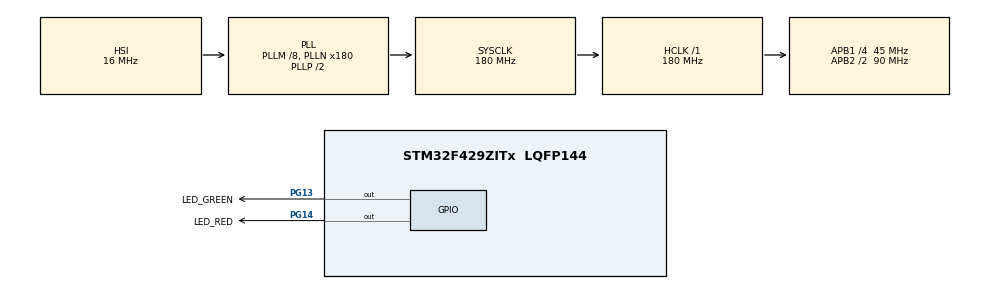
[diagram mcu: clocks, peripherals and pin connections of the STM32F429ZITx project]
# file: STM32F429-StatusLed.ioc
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Mcu.Family=STM32F4
Mcu.Name=STM32F429ZITx
Mcu.Package=LQFP144
NVIC.PriorityGroup=NVIC_PRIORITYGROUP_4
PG13.GPIO_Label=LED_GREEN
PG13.Signal=GPIO_Output
PG14.GPIO_Label=LED_RED
PG14.Signal=GPIO_Output
ProjectManager.HeapSize=0x200
ProjectManager.StackSize=0x400
ProjectManager.TargetToolchain=MDK-ARM V5.27
RCC.48MHZClocksFreq_Value=120000000
RCC.AHBFreq_Value=180000000
RCC.APB1CLKDivider=RCC_HCLK_DIV4
RCC.APB1Freq_Value=45000000
RCC.APB1TimFreq_Value=90000000
RCC.APB2CLKDivider=RCC_HCLK_DIV2
RCC.APB2Freq_Value=90000000
RCC.APB2TimFreq_Value=180000000
RCC.CortexFreq_Value=180000000
RCC.HCLKFreq_Value=180000000
RCC.HSE_VALUE=8000000
RCC.HSI_VALUE=16000000
RCC.LSE_VALUE=32768
RCC.PLLM=8
RCC.PLLN=180
RCC.PLLQ=3
RCC.PLLSAIN=50
RCC.SYSCLKFreq_VALUE=180000000
RCC.SYSCLKSource=RCC_SYSCLKSOURCE_PLLCLK
RCC.VCOOutputFreq_Value=360000000
board=STM32F429I-DISC1

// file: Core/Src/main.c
/* USER CODE BEGIN Header */
/**
  ******************************************************************************
  * @file           : main.c
  * @brief          : Main program body
  ******************************************************************************
  * @attention
  *
  * <h2><center>&copy; Copyright (c) 2022 STMicroelectronics.
  * All rights reserved.</center></h2>
  *
  * This software component is licensed by ST under BSD 3-Clause license,
  * the "License"; You may not use this file except in compliance with the
  * License. You may obtain a copy of the License at:
  *                        opensource.org/licenses/BSD-3-Clause
  *
  ******************************************************************************
  */
/* USER CODE END Header */
#include "main.h"

/* USER CODE BEGIN Includes */
#include "StatusLed.h"
/* USER CODE END Includes */

/* USER CODE BEGIN PV */
// On-Off 500 ms
static const StatusLed_Cycle PATTERN_0_CYCLES[] = {
  {500, 500}
};
static const StatusLed_Pattern PATTERN_0 = STATUS_LED_PATTERN(PATTERN_0_CYCLES);

static const StatusLed_Cycle PATTERN_1_CYCLES[] = {
  {100, 3000}
};
static const StatusLed_Pattern PATTERN_1 = STATUS_LED_PATTERN(PATTERN_1_CYCLES);

static const StatusLed_Cycle PATTERN_2_CYCLES[] = {
  {100, 200},
  {100, 200},
  {100, 3000},
};
static const StatusLed_Pattern PATTERN_2 = STATUS_LED_PATTERN(PATTERN_2_CYCLES);

static const StatusLed_PinConfig LED_RED = {
  LED_RED_GPIO_Port, LED_RED_Pin,
};
static const StatusLed_PinConfig LED_GREEN = {
  LED_GREEN_GPIO_Port, LED_GREEN_Pin,
};

#if STATUS_LED_MAX_NUM == -1
  static StatusLed ledRed;
  static StatusLed ledGreen;
#else
  static StatusLed* ledRed;
  static StatusLed* ledGreen;
#endif

/* USER CODE END PV */

void SystemClock_Config(void);
static void MX_GPIO_Init(void);
/* USER CODE BEGIN PFP */
void StatusLed_initPin(const StatusLed_PinConfig* config);
void StatusLed_deInitPin(const StatusLed_PinConfig* config);
void StatusLed_writePin(const StatusLed_PinConfig* config, StatusLed_PinState state);
StatusLed_Timestamp StatusLed_getTimestamp(void);

void StatusLed_onPatternFinish(StatusLed* led);

/* USER CODE END PFP */

/* USER CODE BEGIN 0 */
static const StatusLed_Driver STATUS_LED_DRIVER = {
  StatusLed_getTimestamp,
  StatusLed_initPin,
  StatusLed_writePin,
#if STATUS_LED_DEINIT
  StatusLed_deInitPin,
#endif
};
/* USER CODE END 0 */

int main(void)
{

  /* MCU Configuration--------------------------------------------------------*/

  /* Reset of all peripherals, Initializes the Flash interface and the Systick. */
  HAL_Init();

  /* Configure the system clock */
  SystemClock_Config();

  /* Initialize all configured peripherals */
  MX_GPIO_Init();
  /* USER CODE BEGIN 2 */
  StatusLed_init(&STATUS_LED_DRIVER);
 #if STATUS_LED_MAX_NUM == -1
  StatusLed_add(&ledRed, &LED_RED);
  StatusLed_add(&ledGreen, &LED_GREEN);

  StatusLed_setPattern(&ledRed, &PATTERN_0);
  StatusLed_setPattern(&ledGreen, &PATTERN_2);
 #else
  ledRed = StatusLed_new();
  StatusLed_add(ledRed, &LED_RED);
  ledGreen = StatusLed_new();
  StatusLed_add(ledGreen, &LED_GREEN);

  StatusLed_setPattern(ledRed, &PATTERN_0);
  StatusLed_setPattern(ledGreen, &PATTERN_1);
 #endif
  /* USER CODE END 2 */

  /* Infinite loop */
  /* USER CODE BEGIN WHILE */
  while (1)
  {
    HAL_Delay(StatusLed_handle());
    /* USER CODE END WHILE */

  }
}

void SystemClock_Config(void)
{
  RCC_OscInitTypeDef RCC_OscInitStruct = {0};
  RCC_ClkInitTypeDef RCC_ClkInitStruct = {0};

  /** Configure the main internal regulator output voltage
  */
  __HAL_RCC_PWR_CLK_ENABLE();
  __HAL_PWR_VOLTAGESCALING_CONFIG(PWR_REGULATOR_VOLTAGE_SCALE1);
  /** Initializes the RCC Oscillators according to the specified parameters
  * in the RCC_OscInitTypeDef structure.
  */
  RCC_OscInitStruct.OscillatorType = RCC_OSCILLATORTYPE_HSI;
  RCC_OscInitStruct.HSIState = RCC_HSI_ON;
  RCC_OscInitStruct.HSICalibrationValue = RCC_HSICALIBRATION_DEFAULT;
  RCC_OscInitStruct.PLL.PLLState = RCC_PLL_ON;
  RCC_OscInitStruct.PLL.PLLSource = RCC_PLLSOURCE_HSI;
  RCC_OscInitStruct.PLL.PLLM = 8;
  RCC_OscInitStruct.PLL.PLLN = 180;
  RCC_OscInitStruct.PLL.PLLP = RCC_PLLP_DIV2;
  RCC_OscInitStruct.PLL.PLLQ = 3;
  if (HAL_RCC_OscConfig(&RCC_OscInitStruct) != HAL_OK)
  {
    Error_Handler();
  }
  /** Activate the Over-Drive mode
  */
  if (HAL_PWREx_EnableOverDrive() != HAL_OK)
  {
    Error_Handler();
  }
  /** Initializes the CPU, AHB and APB buses clocks
  */
  RCC_ClkInitStruct.ClockType = RCC_CLOCKTYPE_HCLK|RCC_CLOCKTYPE_SYSCLK
                              |RCC_CLOCKTYPE_PCLK1|RCC_CLOCKTYPE_PCLK2;
  RCC_ClkInitStruct.SYSCLKSource = RCC_SYSCLKSOURCE_PLLCLK;
  RCC_ClkInitStruct.AHBCLKDivider = RCC_SYSCLK_DIV1;
  RCC_ClkInitStruct.APB1CLKDivider = RCC_HCLK_DIV4;
  RCC_ClkInitStruct.APB2CLKDivider = RCC_HCLK_DIV2;

  if (HAL_RCC_ClockConfig(&RCC_ClkInitStruct, FLASH_LATENCY_5) != HAL_OK)
  {
    Error_Handler();
  }
}

static void MX_GPIO_Init(void)
{
  GPIO_InitTypeDef GPIO_InitStruct = {0};

  /* GPIO Ports Clock Enable */
  __HAL_RCC_GPIOG_CLK_ENABLE();

  /*Configure GPIO pin Output Level */
  HAL_GPIO_WritePin(GPIOG, LED_GREEN_Pin|LED_RED_Pin, GPIO_PIN_RESET);

  /*Configure GPIO pins : LED_GREEN_Pin LED_RED_Pin */
  GPIO_InitStruct.Pin = LED_GREEN_Pin|LED_RED_Pin;
  GPIO_InitStruct.Mode = GPIO_MODE_OUTPUT_PP;
  GPIO_InitStruct.Pull = GPIO_NOPULL;
  GPIO_InitStruct.Speed = GPIO_SPEED_FREQ_LOW;
  HAL_GPIO_Init(GPIOG, &GPIO_InitStruct);

}

/* USER CODE BEGIN 4 */
void StatusLed_initPin(const StatusLed_PinConfig* config) {
  GPIO_InitTypeDef GPIO_InitStruct = {0};

  GPIO_InitStruct.Pin = config->Pin;
  GPIO_InitStruct.Mode = GPIO_MODE_OUTPUT_PP;
  GPIO_InitStruct.Pull = GPIO_NOPULL;
  GPIO_InitStruct.Speed = GPIO_SPEED_FREQ_LOW;
  HAL_GPIO_Init((GPIO_TypeDef*) config->IO, &GPIO_InitStruct);
}
void StatusLed_deInitPin(const StatusLed_PinConfig* config) {
  HAL_GPIO_DeInit((GPIO_TypeDef*) config->IO, config->Pin);
}
void StatusLed_writePin(const StatusLed_PinConfig* config, StatusLed_PinState state) {
  HAL_GPIO_WritePin((GPIO_TypeDef*) config->IO, config->Pin, (GPIO_PinState) state);
}
StatusLed_Timestamp StatusLed_getTimestamp(void) {
  return (StatusLed_Timestamp) HAL_GetTick();
}

void StatusLed_onPatternFinish(StatusLed* led) {

}
/* USER CODE END 4 */

void Error_Handler(void)
{
  __disable_irq();
  while (1)
  {
  }
}

/************************ (C) COPYRIGHT STMicroelectronics *****END OF FILE****/
